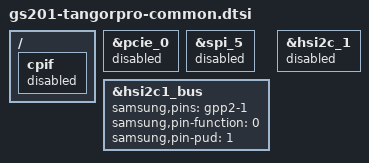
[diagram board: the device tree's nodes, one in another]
// SPDX-License-Identifier: GPL-2.0-only
/*
 * tangorpro device tree source
 *
 * Copyright 2022 Google,LLC
 */

#include <dt-bindings/regulator/samsung,s2mpg-regulator.h>

#include "gs201/gs201-common.dtsi"
#include "gs201/gs201-cloudripper-battery.dtsi"
#include "gs201/gs201-cloudripper-bcl.dtsi"
#include "gs201/gs201-cloudripper-gsa-gsc.dtsi"
#include "gs201/gs201-cloudripper-wlan.dtsi"

#include "gs201/gs201-pantah-pmic.dtsi"

#include "gs201-tangorpro-uwb.dtsi"
#include "gs201-tangorpro-camera-pmic.dtsi"
#include "gs201-tangorpro-camera.dtsi"
#include "gs201-tangorpro-display.dtsi"
#include "gs201-tangorpro-pmic.dtsi"
#include "gs201-tangorpro-touch.dtsi"
#include "gs201-tangorpro-thermal.dtsi"
#include "gs201-tangorpro-audio.dtsi"
#include "gs201-tangorpro-battery.dtsi"
#include "gs201/gs101-faceauth-dma-heap.dtsi"
#include "gs201-tangorpro-charging.dtsi"
#include "gs201-tangorpro-usb.dtsi"
#include "gs201-tangorpro-usecases.dtsi"
#include "gs201-tangorpro-wlan.dtsi"
#include "gs201-tangorpro-led.dtsi"
#include "gs201-tangorpro-fingerprint.dtsi"
#include "gs201-tangorpro-sbbm.dtsi"
#include "gs201-tangorpro-typec.dtsi"
#include "gs201-pogo-transport.dtsi"

/ {
	fragment@modemif {
		target-path = "/";
		__overlay__ {
			#address-cells = <2>;
			#size-cells = <1>;
			cpif {
				status = "disabled";
			};
		};
	};
};

&pcie_0 {
	status = "disabled";
};

&spi_5 {
	status = "disabled";
};

// Configurate gpp2-1 as default input and pull-down
&hsi2c1_bus {
	samsung,pins = "gpp2-1";
	samsung,pin-function = <0>;
	samsung,pin-pud = <1>;
};

// Disabled hsi2c_1 due to no module stmvl53l1 (ldaf-irq)
&hsi2c_1 {
	status = "disabled";
};
